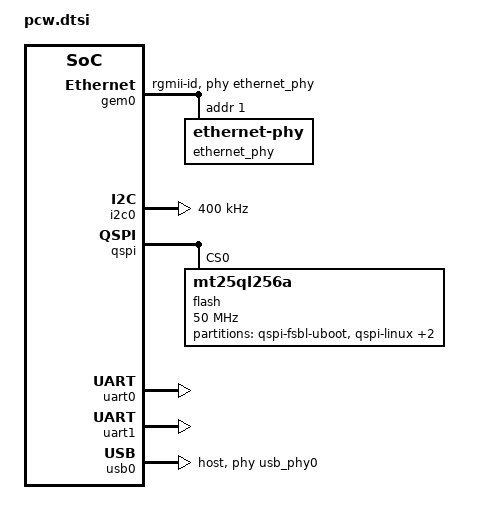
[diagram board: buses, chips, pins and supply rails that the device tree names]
/*
 * CAUTION: This file is automatically generated by Xilinx.
 * Version:  
 * Today is: Thu Jul 18 09:45:21 2024
 */


/ {
	cpus {
		cpu@0 {
			operating-points = <666666 1000000 333333 1000000>;
		};
	};
};

&gem0 {
	status = "okay";
	phy-mode = "rgmii-id";
	phy-handle = <&ethernet_phy>;
	local-mac-address = [00 0a 35 00 00 00];
	ethernet_phy: ethernet-phy@1 {
		reg = <1>;
		device_type = "ethernet-phy";
	};
};

&gpio0 {
	emio-gpio-width = <2>;
	gpio-mask-high = <0x0>;
	gpio-mask-low = <0x5600>;
};

&i2c0 {
	clock-frequency = <400000>;
	status = "okay";
};

&intc {
	num_cpus = <2>;
	num_interrupts = <96>;
};

&qspi {
	u-boot,dm-pre-reloc;
	status = "okay";
	is-dual = <0>;
	num-cs = <1>;
	flash@0 {
		compatible = "mt25ql256a";
		reg = <0x0>;
		spi-tx-bus-width = <4>;
		spi-rx-bus-width = <4>;
		spi-max-frequency = <50000000>;
		#address-cells = <1>;
		#size-cells = <1>;
		partition@0 {
			label = "qspi-fsbl-uboot";
			reg = <0x0 0x100000>;
		};
		partition@100000 {
			label = "qspi-linux";
			reg = <0x100000 0x400000>;/* 0x400000 */
		};
		partition@500000 {
			label = "qspi-device-tree";
			reg = <0x500000 0x20000>;/* 0x620000 */
		};
		partition@520000 {
			label = "qspi-rootfs";
			reg = <0x520000 0x800000>;
		};
	};
};

&uart0 {
        cts-override ;
        device_type = "serial";
        port-number = <0>;
        status = "okay";
        u-boot,dm-pre-reloc;
};

&uart1 {
	device_type = "serial";
	port-number = <19>;
	status = "okay";
};

&usb0 {
	phy_type = "ulpi";
	status = "okay";
	dr_mode = "host";
	usb-phy = <&usb_phy0>;
	usb-reset = <&gpio0 40 0>;
};

&clkc {
	fclk-enable = <0x1>;
	ps-clk-frequency = <33333333>;
};

&watchdog0 {
	reset-on-timeout;
};
